AUTOSAR XML (schema 4-0-3)
standard types defined: Boolean, UInt16
package /AUTOSAR_Platform/DataConstrs
  range DC_Boolean: raw 0..1
  range DC_UInt16: raw 0..65535
package /PATAC/MSM/ComponentTypes
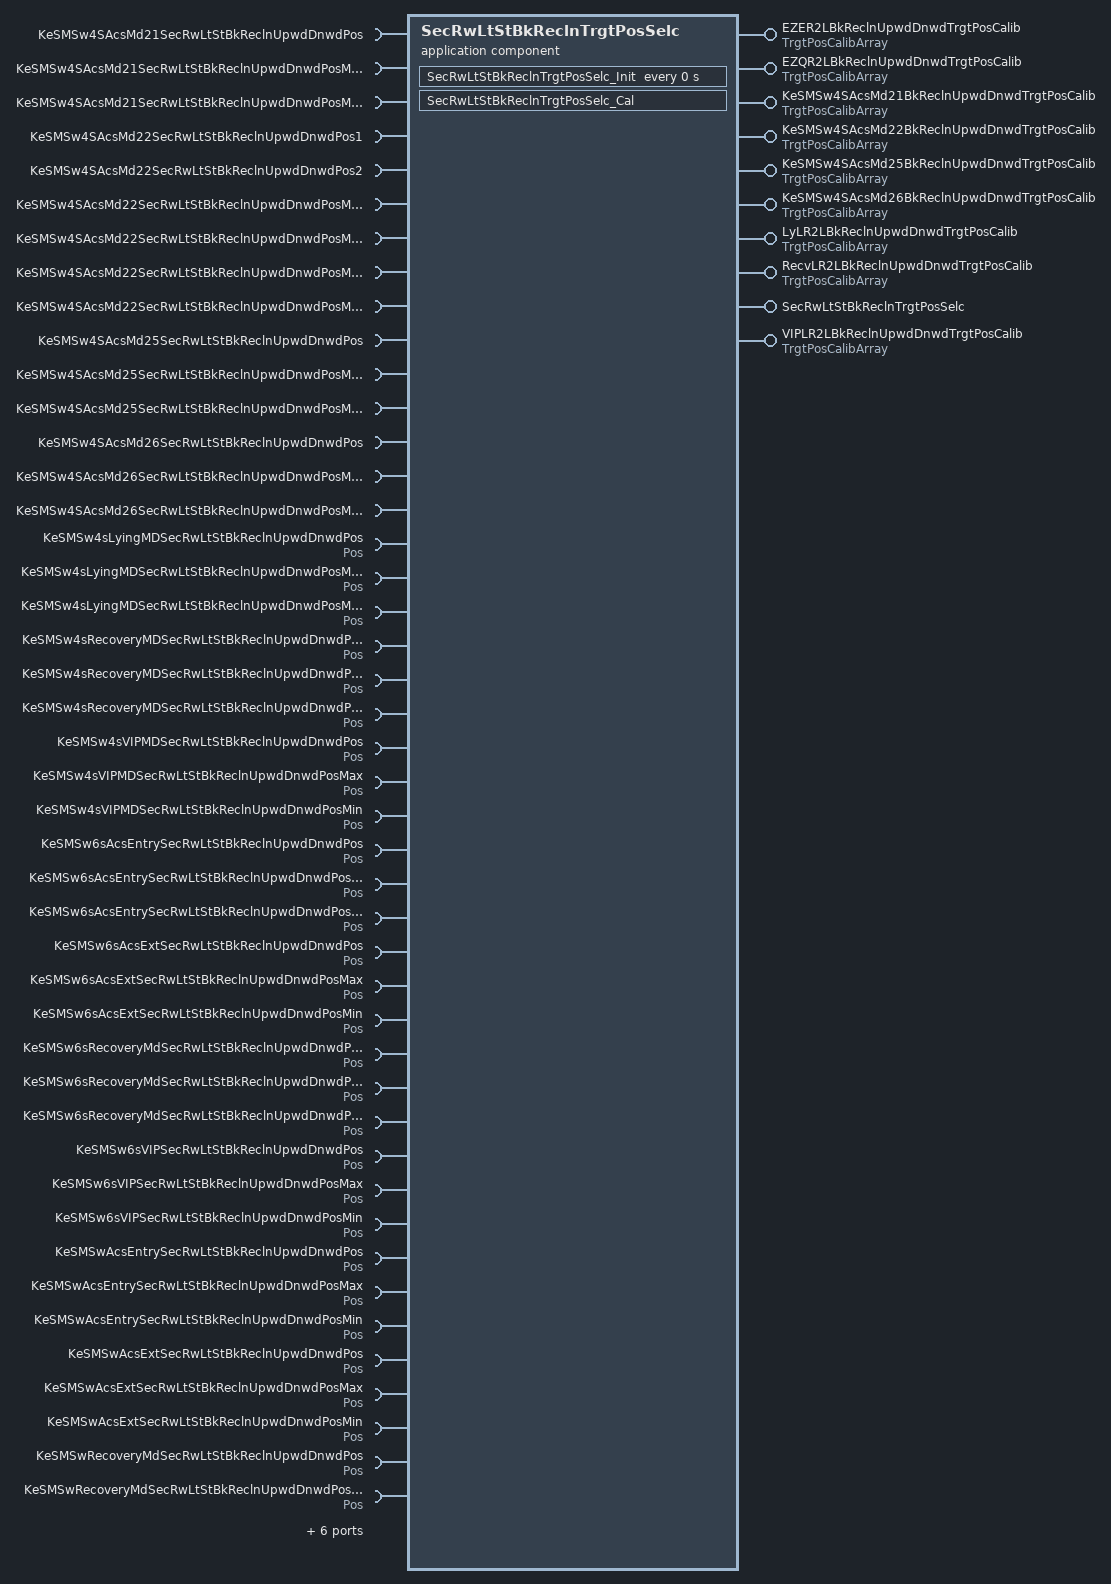
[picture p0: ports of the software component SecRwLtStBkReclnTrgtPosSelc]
  application sw component type SecRwLtStBkReclnTrgtPosSelc
    10 x provide port:
      EZER2LBkReclnUpwdDnwdTrgtPosCalib: nonqueued-sender-com-spec{data-element=TrgtPosArray, init-value=[4095, 4095, 4095]}, provided-interface=TrgtPosCalibArray
      EZQR2LBkReclnUpwdDnwdTrgtPosCalib: nonqueued-sender-com-spec{data-element=TrgtPosArray, init-value=[4095, 4095, 4095]}, provided-interface=TrgtPosCalibArray
      KeSMSw4SAcsMd21BkReclnUpwdDnwdTrgtPosCalib: nonqueued-sender-com-spec{data-element=TrgtPosArray, init-value=[4095, 4095, 4095]}, provided-interface=TrgtPosCalibArray
      KeSMSw4SAcsMd22BkReclnUpwdDnwdTrgtPosCalib: nonqueued-sender-com-spec{data-element=TrgtPosArray, init-value=[4095, 4095, 4095]}, provided-interface=TrgtPosCalibArray
      KeSMSw4SAcsMd25BkReclnUpwdDnwdTrgtPosCalib: nonqueued-sender-com-spec{data-element=TrgtPosArray, init-value=[4095, 4095, 4095]}, provided-interface=TrgtPosCalibArray
      KeSMSw4SAcsMd26BkReclnUpwdDnwdTrgtPosCalib: nonqueued-sender-com-spec{data-element=TrgtPosArray, init-value=[4095, 4095, 4095]}, provided-interface=TrgtPosCalibArray
      LyLR2LBkReclnUpwdDnwdTrgtPosCalib: nonqueued-sender-com-spec{data-element=TrgtPosArray, init-value=[4095, 4095, 4095]}, provided-interface=TrgtPosCalibArray
      RecvLR2LBkReclnUpwdDnwdTrgtPosCalib: nonqueued-sender-com-spec{data-element=TrgtPosArray, init-value=[4095, 4095, 4095]}, provided-interface=TrgtPosCalibArray
      SecRwLtStBkReclnTrgtPosSelc: server-com-spec{operation=Cal, queue-length=1}, provided-interface=SecRwLtStBkReclnTrgtPosSelc
      VIPLR2LBkReclnUpwdDnwdTrgtPosCalib: nonqueued-sender-com-spec{data-element=TrgtPosArray, init-value=[4095, 4095, 4095]}, provided-interface=TrgtPosCalibArray
    50 x require port:
      KeSMSw4SAcsMd21SecRwLtStBkReclnUpwdDnwdPos: parameter-require-com-spec{init-value=0, parameter=KeSMSw4SAcsMd21SecRwLtStBkReclnUpwdDnwdPos/Val}, required-interface=KeSMSw4SAcsMd21SecRwLtStBkReclnUpwdDnwdPos
      KeSMSw4SAcsMd21SecRwLtStBkReclnUpwdDnwdPosMax: parameter-require-com-spec{init-value=0, parameter=KeSMSw4SAcsMd21SecRwLtStBkReclnUpwdDnwdPosMax/Val}, required-interface=KeSMSw4SAcsMd21SecRwLtStBkReclnUpwdDnwdPosMax
      KeSMSw4SAcsMd21SecRwLtStBkReclnUpwdDnwdPosMin: parameter-require-com-spec{init-value=0, parameter=KeSMSw4SAcsMd21SecRwLtStBkReclnUpwdDnwdPosMin/Val}, required-interface=KeSMSw4SAcsMd21SecRwLtStBkReclnUpwdDnwdPosMin
      KeSMSw4SAcsMd22SecRwLtStBkReclnUpwdDnwdPos1: parameter-require-com-spec{init-value=0, parameter=KeSMSw4SAcsMd22SecRwLtStBkReclnUpwdDnwdPos1/Val}, required-interface=KeSMSw4SAcsMd22SecRwLtStBkReclnUpwdDnwdPos1
      KeSMSw4SAcsMd22SecRwLtStBkReclnUpwdDnwdPos2: parameter-require-com-spec{init-value=0, parameter=KeSMSw4SAcsMd22SecRwLtStBkReclnUpwdDnwdPos2/Val}, required-interface=KeSMSw4SAcsMd22SecRwLtStBkReclnUpwdDnwdPos2
      KeSMSw4SAcsMd22SecRwLtStBkReclnUpwdDnwdPosMax1: parameter-require-com-spec{init-value=0, parameter=KeSMSw4SAcsMd22SecRwLtStBkReclnUpwdDnwdPosMax1/Val}, required-interface=KeSMSw4SAcsMd22SecRwLtStBkReclnUpwdDnwdPosMax1
      KeSMSw4SAcsMd22SecRwLtStBkReclnUpwdDnwdPosMax2: parameter-require-com-spec{init-value=0, parameter=KeSMSw4SAcsMd22SecRwLtStBkReclnUpwdDnwdPosMax2/Val}, required-interface=KeSMSw4SAcsMd22SecRwLtStBkReclnUpwdDnwdPosMax2
      KeSMSw4SAcsMd22SecRwLtStBkReclnUpwdDnwdPosMin1: parameter-require-com-spec{init-value=0, parameter=KeSMSw4SAcsMd22SecRwLtStBkReclnUpwdDnwdPosMin1/Val}, required-interface=KeSMSw4SAcsMd22SecRwLtStBkReclnUpwdDnwdPosMin1
      KeSMSw4SAcsMd22SecRwLtStBkReclnUpwdDnwdPosMin2: parameter-require-com-spec{init-value=0, parameter=KeSMSw4SAcsMd22SecRwLtStBkReclnUpwdDnwdPosMin2/Val}, required-interface=KeSMSw4SAcsMd22SecRwLtStBkReclnUpwdDnwdPosMin2
      KeSMSw4SAcsMd25SecRwLtStBkReclnUpwdDnwdPos: parameter-require-com-spec{init-value=0, parameter=KeSMSw4SAcsMd25SecRwLtStBkReclnUpwdDnwdPos/Val}, required-interface=KeSMSw4SAcsMd25SecRwLtStBkReclnUpwdDnwdPos
      KeSMSw4SAcsMd25SecRwLtStBkReclnUpwdDnwdPosMax: parameter-require-com-spec{init-value=0, parameter=KeSMSw4SAcsMd25SecRwLtStBkReclnUpwdDnwdPosMax/Val}, required-interface=KeSMSw4SAcsMd25SecRwLtStBkReclnUpwdDnwdPosMax
      KeSMSw4SAcsMd25SecRwLtStBkReclnUpwdDnwdPosMin: parameter-require-com-spec{init-value=0, parameter=KeSMSw4SAcsMd25SecRwLtStBkReclnUpwdDnwdPosMin/Val}, required-interface=KeSMSw4SAcsMd25SecRwLtStBkReclnUpwdDnwdPosMin
      KeSMSw4SAcsMd26SecRwLtStBkReclnUpwdDnwdPos: parameter-require-com-spec{init-value=0, parameter=KeSMSw4SAcsMd26SecRwLtStBkReclnUpwdDnwdPos/Val}, required-interface=KeSMSw4SAcsMd26SecRwLtStBkReclnUpwdDnwdPos
      KeSMSw4SAcsMd26SecRwLtStBkReclnUpwdDnwdPosMax: parameter-require-com-spec{init-value=0, parameter=KeSMSw4SAcsMd26SecRwLtStBkReclnUpwdDnwdPosMax/Val}, required-interface=KeSMSw4SAcsMd26SecRwLtStBkReclnUpwdDnwdPosMax
      KeSMSw4SAcsMd26SecRwLtStBkReclnUpwdDnwdPosMin: parameter-require-com-spec{init-value=0, parameter=KeSMSw4SAcsMd26SecRwLtStBkReclnUpwdDnwdPosMin/Val}, required-interface=KeSMSw4SAcsMd26SecRwLtStBkReclnUpwdDnwdPosMin
      KeSMSw4sLyingMDSecRwLtStBkReclnUpwdDnwdPos: parameter-require-com-spec{init-value=0, parameter=Pos/Val}, required-interface=Pos
      KeSMSw4sLyingMDSecRwLtStBkReclnUpwdDnwdPosMax: parameter-require-com-spec{init-value=0, parameter=Pos/Val}, required-interface=Pos
      KeSMSw4sLyingMDSecRwLtStBkReclnUpwdDnwdPosMin: parameter-require-com-spec{init-value=0, parameter=Pos/Val}, required-interface=Pos
      KeSMSw4sRecoveryMDSecRwLtStBkReclnUpwdDnwdPos: parameter-require-com-spec{init-value=0, parameter=Pos/Val}, required-interface=Pos
      KeSMSw4sRecoveryMDSecRwLtStBkReclnUpwdDnwdPosMax: parameter-require-com-spec{init-value=0, parameter=Pos/Val}, required-interface=Pos
      KeSMSw4sRecoveryMDSecRwLtStBkReclnUpwdDnwdPosMin: parameter-require-com-spec{init-value=0, parameter=Pos/Val}, required-interface=Pos
      KeSMSw4sVIPMDSecRwLtStBkReclnUpwdDnwdPos: parameter-require-com-spec{init-value=0, parameter=Pos/Val}, required-interface=Pos
      KeSMSw4sVIPMDSecRwLtStBkReclnUpwdDnwdPosMax: parameter-require-com-spec{init-value=0, parameter=Pos/Val}, required-interface=Pos
      KeSMSw4sVIPMDSecRwLtStBkReclnUpwdDnwdPosMin: parameter-require-com-spec{init-value=0, parameter=Pos/Val}, required-interface=Pos
      KeSMSw6sAcsEntrySecRwLtStBkReclnUpwdDnwdPos: parameter-require-com-spec{init-value=1280, parameter=Pos/Val}, required-interface=Pos
      KeSMSw6sAcsEntrySecRwLtStBkReclnUpwdDnwdPosMax: parameter-require-com-spec{init-value=1280, parameter=Pos/Val}, required-interface=Pos
      KeSMSw6sAcsEntrySecRwLtStBkReclnUpwdDnwdPosMin: parameter-require-com-spec{init-value=0, parameter=Pos/Val}, required-interface=Pos
      KeSMSw6sAcsExtSecRwLtStBkReclnUpwdDnwdPos: parameter-require-com-spec{init-value=1280, parameter=Pos/Val}, required-interface=Pos
      KeSMSw6sAcsExtSecRwLtStBkReclnUpwdDnwdPosMax: parameter-require-com-spec{init-value=1280, parameter=Pos/Val}, required-interface=Pos
      KeSMSw6sAcsExtSecRwLtStBkReclnUpwdDnwdPosMin: parameter-require-com-spec{init-value=0, parameter=Pos/Val}, required-interface=Pos
      KeSMSw6sRecoveryMdSecRwLtStBkReclnUpwdDnwdPos: parameter-require-com-spec{init-value=1268, parameter=Pos/Val}, required-interface=Pos
      KeSMSw6sRecoveryMdSecRwLtStBkReclnUpwdDnwdPosMax: parameter-require-com-spec{init-value=1268, parameter=Pos/Val}, required-interface=Pos
      KeSMSw6sRecoveryMdSecRwLtStBkReclnUpwdDnwdPosMin: parameter-require-com-spec{init-value=0, parameter=Pos/Val}, required-interface=Pos
      KeSMSw6sVIPSecRwLtStBkReclnUpwdDnwdPos: parameter-require-com-spec{init-value=1960, parameter=Pos/Val}, required-interface=Pos
      KeSMSw6sVIPSecRwLtStBkReclnUpwdDnwdPosMax: parameter-require-com-spec{init-value=1960, parameter=Pos/Val}, required-interface=Pos
      KeSMSw6sVIPSecRwLtStBkReclnUpwdDnwdPosMin: parameter-require-com-spec{init-value=1960, parameter=Pos/Val}, required-interface=Pos
      KeSMSwAcsEntrySecRwLtStBkReclnUpwdDnwdPos: parameter-require-com-spec{init-value=1280, parameter=Pos/Val}, required-interface=Pos
      KeSMSwAcsEntrySecRwLtStBkReclnUpwdDnwdPosMax: parameter-require-com-spec{init-value=1280, parameter=Pos/Val}, required-interface=Pos
      KeSMSwAcsEntrySecRwLtStBkReclnUpwdDnwdPosMin: parameter-require-com-spec{init-value=0, parameter=Pos/Val}, required-interface=Pos
      KeSMSwAcsExtSecRwLtStBkReclnUpwdDnwdPos: parameter-require-com-spec{init-value=1280, parameter=Pos/Val}, required-interface=Pos
      KeSMSwAcsExtSecRwLtStBkReclnUpwdDnwdPosMax: parameter-require-com-spec{init-value=1280, parameter=Pos/Val}, required-interface=Pos
      KeSMSwAcsExtSecRwLtStBkReclnUpwdDnwdPosMin: parameter-require-com-spec{init-value=0, parameter=Pos/Val}, required-interface=Pos
      KeSMSwRecoveryMdSecRwLtStBkReclnUpwdDnwdPos: parameter-require-com-spec{init-value=1268, parameter=Pos/Val}, required-interface=Pos
      KeSMSwRecoveryMdSecRwLtStBkReclnUpwdDnwdPosMax: parameter-require-com-spec{init-value=1268, parameter=Pos/Val}, required-interface=Pos
      KeSMSwRecoveryMdSecRwLtStBkReclnUpwdDnwdPosMin: parameter-require-com-spec{init-value=0, parameter=Pos/Val}, required-interface=Pos
      KeSMSwVIPSecRwLtStBkReclnUpwdDnwdPos: parameter-require-com-spec{init-value=1960, parameter=Pos/Val}, required-interface=Pos
      KeSMSwVIPSecRwLtStBkReclnUpwdDnwdPosMax: parameter-require-com-spec{init-value=1960, parameter=Pos/Val}, required-interface=Pos
      KeSMSwVIPSecRwLtStBkReclnUpwdDnwdPosMin: parameter-require-com-spec{init-value=1960, parameter=Pos/Val}, required-interface=Pos
      R2LMdSeatOccupied: nonqueued-receiver-com-spec{data-element=Val, filter=data-filter-type=ALWAYS, init-value=0}, required-interface=MdSeatOccupied
      StNumFlg: required-interface=StNumFlg
        required-com-specs:
          data-element=Is4s, filter=data-filter-type=ALWAYS, init-value=0
          data-element=Is6s, filter=data-filter-type=ALWAYS, init-value=0
          data-element=Is6s7s, filter=data-filter-type=ALWAYS, init-value=0
          data-element=Is7s, filter=data-filter-type=ALWAYS, init-value=0
    behavior SecRwLtStBkReclnTrgtPosSelc_InternalBehavior
      operation invoked event OIT_SecRwLtStBkReclnTrgtPosSelc_Cal_SecRwLtStBkReclnTrgtPosSelc_Cal: start-on-event=SecRwLtStBkReclnTrgtPosSelc_Cal, operation=SecRwLtStBkReclnTrgtPosSelc.Cal
      timing event SecRwLtStBkReclnTrgtPosSelc_InitEvent: start-on-event=SecRwLtStBkReclnTrgtPosSelc_Init, period=0
      runnable SecRwLtStBkReclnTrgtPosSelc_Cal
        data-receive-point-by-arguments:
          5 x access:
            REC_R2LMdSeatOccupied_Val: accessed-variable=R2LMdSeatOccupied.Val
            REC_StNumFlg_Is4s: accessed-variable=StNumFlg.Is4s
            REC_StNumFlg_Is6s: accessed-variable=StNumFlg.Is6s
            REC_StNumFlg_Is6s7s: accessed-variable=StNumFlg.Is6s7s
            REC_StNumFlg_Is7s: accessed-variable=StNumFlg.Is7s
        data-send-points:
          9 x access:
            SEND_EZER2LBkReclnUpwdDnwdTrgtPosCalib_TrgtPosArray: accessed-variable=EZER2LBkReclnUpwdDnwdTrgtPosCalib.TrgtPosArray
            SEND_EZQR2LBkReclnUpwdDnwdTrgtPosCalib_TrgtPosArray: accessed-variable=EZQR2LBkReclnUpwdDnwdTrgtPosCalib.TrgtPosArray
            SEND_KeSMSw4SAcsMd21BkReclnUpwdDnwdTrgtPosCalib_TrgtPosArray: accessed-variable=KeSMSw4SAcsMd21BkReclnUpwdDnwdTrgtPosCalib.TrgtPosArray
            SEND_KeSMSw4SAcsMd22BkReclnUpwdDnwdTrgtPosCalib_TrgtPosArray: accessed-variable=KeSMSw4SAcsMd22BkReclnUpwdDnwdTrgtPosCalib.TrgtPosArray
            SEND_KeSMSw4SAcsMd25BkReclnUpwdDnwdTrgtPosCalib_TrgtPosArray: accessed-variable=KeSMSw4SAcsMd25BkReclnUpwdDnwdTrgtPosCalib.TrgtPosArray
            SEND_KeSMSw4SAcsMd26BkReclnUpwdDnwdTrgtPosCalib_TrgtPosArray: accessed-variable=KeSMSw4SAcsMd26BkReclnUpwdDnwdTrgtPosCalib.TrgtPosArray
            SEND_LyLR2LBkReclnUpwdDnwdTrgtPosCalib_TrgtPosArray: accessed-variable=LyLR2LBkReclnUpwdDnwdTrgtPosCalib.TrgtPosArray
            SEND_RecvLR2LBkReclnUpwdDnwdTrgtPosCalib_TrgtPosArray: accessed-variable=RecvLR2LBkReclnUpwdDnwdTrgtPosCalib.TrgtPosArray
            SEND_VIPLR2LBkReclnUpwdDnwdTrgtPosCalib_TrgtPosArray: accessed-variable=VIPLR2LBkReclnUpwdDnwdTrgtPosCalib.TrgtPosArray
        48 x parameter access:
          PA_KeSMSw4SAcsMd21SecRwLtStBkReclnUpwdDnwdPos_Val: accessed-parameter=KeSMSw4SAcsMd21SecRwLtStBkReclnUpwdDnwdPos.Val
          PA_KeSMSw4SAcsMd21SecRwLtStBkReclnUpwdDnwdPosMax_Val: accessed-parameter=KeSMSw4SAcsMd21SecRwLtStBkReclnUpwdDnwdPosMax.Val
          PA_KeSMSw4SAcsMd21SecRwLtStBkReclnUpwdDnwdPosMin_Val: accessed-parameter=KeSMSw4SAcsMd21SecRwLtStBkReclnUpwdDnwdPosMin.Val
          PA_KeSMSw4SAcsMd22SecRwLtStBkReclnUpwdDnwdPos1_Val: accessed-parameter=KeSMSw4SAcsMd22SecRwLtStBkReclnUpwdDnwdPos1.Val
          PA_KeSMSw4SAcsMd22SecRwLtStBkReclnUpwdDnwdPos2_Val: accessed-parameter=KeSMSw4SAcsMd22SecRwLtStBkReclnUpwdDnwdPos2.Val
          PA_KeSMSw4SAcsMd22SecRwLtStBkReclnUpwdDnwdPosMax1_Val: accessed-parameter=KeSMSw4SAcsMd22SecRwLtStBkReclnUpwdDnwdPosMax1.Val
          PA_KeSMSw4SAcsMd22SecRwLtStBkReclnUpwdDnwdPosMax2_Val: accessed-parameter=KeSMSw4SAcsMd22SecRwLtStBkReclnUpwdDnwdPosMax2.Val
          PA_KeSMSw4SAcsMd22SecRwLtStBkReclnUpwdDnwdPosMin1_Val: accessed-parameter=KeSMSw4SAcsMd22SecRwLtStBkReclnUpwdDnwdPosMin1.Val
          PA_KeSMSw4SAcsMd22SecRwLtStBkReclnUpwdDnwdPosMin2_Val: accessed-parameter=KeSMSw4SAcsMd22SecRwLtStBkReclnUpwdDnwdPosMin2.Val
          PA_KeSMSw4SAcsMd25SecRwLtStBkReclnUpwdDnwdPos_Val: accessed-parameter=KeSMSw4SAcsMd25SecRwLtStBkReclnUpwdDnwdPos.Val
          PA_KeSMSw4SAcsMd25SecRwLtStBkReclnUpwdDnwdPosMax_Val: accessed-parameter=KeSMSw4SAcsMd25SecRwLtStBkReclnUpwdDnwdPosMax.Val
          PA_KeSMSw4SAcsMd25SecRwLtStBkReclnUpwdDnwdPosMin_Val: accessed-parameter=KeSMSw4SAcsMd25SecRwLtStBkReclnUpwdDnwdPosMin.Val
          PA_KeSMSw4SAcsMd26SecRwLtStBkReclnUpwdDnwdPos_Val: accessed-parameter=KeSMSw4SAcsMd26SecRwLtStBkReclnUpwdDnwdPos.Val
          PA_KeSMSw4SAcsMd26SecRwLtStBkReclnUpwdDnwdPosMax_Val: accessed-parameter=KeSMSw4SAcsMd26SecRwLtStBkReclnUpwdDnwdPosMax.Val
          PA_KeSMSw4SAcsMd26SecRwLtStBkReclnUpwdDnwdPosMin_Val: accessed-parameter=KeSMSw4SAcsMd26SecRwLtStBkReclnUpwdDnwdPosMin.Val
          PA_KeSMSw4sLyingMDSecRwLtStBkReclnUpwdDnwdPos_Val: accessed-parameter=KeSMSw4sLyingMDSecRwLtStBkReclnUpwdDnwdPos.Val
          PA_KeSMSw4sLyingMDSecRwLtStBkReclnUpwdDnwdPosMax_Val: accessed-parameter=KeSMSw4sLyingMDSecRwLtStBkReclnUpwdDnwdPosMax.Val
          PA_KeSMSw4sLyingMDSecRwLtStBkReclnUpwdDnwdPosMin_Val: accessed-parameter=KeSMSw4sLyingMDSecRwLtStBkReclnUpwdDnwdPosMin.Val
          PA_KeSMSw4sRecoveryMDSecRwLtStBkReclnUpwdDnwdPos_Val: accessed-parameter=KeSMSw4sRecoveryMDSecRwLtStBkReclnUpwdDnwdPos.Val
          PA_KeSMSw4sRecoveryMDSecRwLtStBkReclnUpwdDnwdPosMax_Val: accessed-parameter=KeSMSw4sRecoveryMDSecRwLtStBkReclnUpwdDnwdPosMax.Val
          PA_KeSMSw4sRecoveryMDSecRwLtStBkReclnUpwdDnwdPosMin_Val: accessed-parameter=KeSMSw4sRecoveryMDSecRwLtStBkReclnUpwdDnwdPosMin.Val
          PA_KeSMSw4sVIPMDSecRwLtStBkReclnUpwdDnwdPos_Val: accessed-parameter=KeSMSw4sVIPMDSecRwLtStBkReclnUpwdDnwdPos.Val
          PA_KeSMSw4sVIPMDSecRwLtStBkReclnUpwdDnwdPosMax_Val: accessed-parameter=KeSMSw4sVIPMDSecRwLtStBkReclnUpwdDnwdPosMax.Val
          PA_KeSMSw4sVIPMDSecRwLtStBkReclnUpwdDnwdPosMin_Val: accessed-parameter=KeSMSw4sVIPMDSecRwLtStBkReclnUpwdDnwdPosMin.Val
          PA_KeSMSw6sAcsEntrySecRwLtStBkReclnUpwdDnwdPos_Val: accessed-parameter=KeSMSw6sAcsEntrySecRwLtStBkReclnUpwdDnwdPos.Val
          PA_KeSMSw6sAcsEntrySecRwLtStBkReclnUpwdDnwdPosMax_Val: accessed-parameter=KeSMSw6sAcsEntrySecRwLtStBkReclnUpwdDnwdPosMax.Val
          PA_KeSMSw6sAcsEntrySecRwLtStBkReclnUpwdDnwdPosMin_Val: accessed-parameter=KeSMSw6sAcsEntrySecRwLtStBkReclnUpwdDnwdPosMin.Val
          PA_KeSMSw6sAcsExtSecRwLtStBkReclnUpwdDnwdPos_Val: accessed-parameter=KeSMSw6sAcsExtSecRwLtStBkReclnUpwdDnwdPos.Val
          PA_KeSMSw6sAcsExtSecRwLtStBkReclnUpwdDnwdPosMax_Val: accessed-parameter=KeSMSw6sAcsExtSecRwLtStBkReclnUpwdDnwdPosMax.Val
          PA_KeSMSw6sAcsExtSecRwLtStBkReclnUpwdDnwdPosMin_Val: accessed-parameter=KeSMSw6sAcsExtSecRwLtStBkReclnUpwdDnwdPosMin.Val
          PA_KeSMSw6sRecoveryMdSecRwLtStBkReclnUpwdDnwdPos_Val: accessed-parameter=KeSMSw6sRecoveryMdSecRwLtStBkReclnUpwdDnwdPos.Val
          PA_KeSMSw6sRecoveryMdSecRwLtStBkReclnUpwdDnwdPosMax_Val: accessed-parameter=KeSMSw6sRecoveryMdSecRwLtStBkReclnUpwdDnwdPosMax.Val
          PA_KeSMSw6sRecoveryMdSecRwLtStBkReclnUpwdDnwdPosMin_Val: accessed-parameter=KeSMSw6sRecoveryMdSecRwLtStBkReclnUpwdDnwdPosMin.Val
          PA_KeSMSw6sVIPSecRwLtStBkReclnUpwdDnwdPos_Val: accessed-parameter=KeSMSw6sVIPSecRwLtStBkReclnUpwdDnwdPos.Val
          PA_KeSMSw6sVIPSecRwLtStBkReclnUpwdDnwdPosMax_Val: accessed-parameter=KeSMSw6sVIPSecRwLtStBkReclnUpwdDnwdPosMax.Val
          PA_KeSMSw6sVIPSecRwLtStBkReclnUpwdDnwdPosMin_Val: accessed-parameter=KeSMSw6sVIPSecRwLtStBkReclnUpwdDnwdPosMin.Val
          PA_KeSMSwAcsEntrySecRwLtStBkReclnUpwdDnwdPos_Val: accessed-parameter=KeSMSwAcsEntrySecRwLtStBkReclnUpwdDnwdPos.Val
          PA_KeSMSwAcsEntrySecRwLtStBkReclnUpwdDnwdPosMax_Val: accessed-parameter=KeSMSwAcsEntrySecRwLtStBkReclnUpwdDnwdPosMax.Val
          PA_KeSMSwAcsEntrySecRwLtStBkReclnUpwdDnwdPosMin_Val: accessed-parameter=KeSMSwAcsEntrySecRwLtStBkReclnUpwdDnwdPosMin.Val
          PA_KeSMSwAcsExtSecRwLtStBkReclnUpwdDnwdPos_Val: accessed-parameter=KeSMSwAcsExtSecRwLtStBkReclnUpwdDnwdPos.Val
          PA_KeSMSwAcsExtSecRwLtStBkReclnUpwdDnwdPosMax_Val: accessed-parameter=KeSMSwAcsExtSecRwLtStBkReclnUpwdDnwdPosMax.Val
          PA_KeSMSwAcsExtSecRwLtStBkReclnUpwdDnwdPosMin_Val: accessed-parameter=KeSMSwAcsExtSecRwLtStBkReclnUpwdDnwdPosMin.Val
          PA_KeSMSwRecoveryMdSecRwLtStBkReclnUpwdDnwdPos_Val: accessed-parameter=KeSMSwRecoveryMdSecRwLtStBkReclnUpwdDnwdPos.Val
          PA_KeSMSwRecoveryMdSecRwLtStBkReclnUpwdDnwdPosMax_Val: accessed-parameter=KeSMSwRecoveryMdSecRwLtStBkReclnUpwdDnwdPosMax.Val
          PA_KeSMSwRecoveryMdSecRwLtStBkReclnUpwdDnwdPosMin_Val: accessed-parameter=KeSMSwRecoveryMdSecRwLtStBkReclnUpwdDnwdPosMin.Val
          PA_KeSMSwVIPSecRwLtStBkReclnUpwdDnwdPos_Val: accessed-parameter=KeSMSwVIPSecRwLtStBkReclnUpwdDnwdPos.Val
          PA_KeSMSwVIPSecRwLtStBkReclnUpwdDnwdPosMax_Val: accessed-parameter=KeSMSwVIPSecRwLtStBkReclnUpwdDnwdPosMax.Val
          PA_KeSMSwVIPSecRwLtStBkReclnUpwdDnwdPosMin_Val: accessed-parameter=KeSMSwVIPSecRwLtStBkReclnUpwdDnwdPosMin.Val
      runnable SecRwLtStBkReclnTrgtPosSelc_Init
        48 x parameter access:
          PA_KeSMSw4SAcsMd21SecRwLtStBkReclnUpwdDnwdPos_Val: accessed-parameter=KeSMSw4SAcsMd21SecRwLtStBkReclnUpwdDnwdPos.Val
          PA_KeSMSw4SAcsMd21SecRwLtStBkReclnUpwdDnwdPosMax_Val: accessed-parameter=KeSMSw4SAcsMd21SecRwLtStBkReclnUpwdDnwdPosMax.Val
          PA_KeSMSw4SAcsMd21SecRwLtStBkReclnUpwdDnwdPosMin_Val: accessed-parameter=KeSMSw4SAcsMd21SecRwLtStBkReclnUpwdDnwdPosMin.Val
          PA_KeSMSw4SAcsMd22SecRwLtStBkReclnUpwdDnwdPos1_Val: accessed-parameter=KeSMSw4SAcsMd22SecRwLtStBkReclnUpwdDnwdPos1.Val
          PA_KeSMSw4SAcsMd22SecRwLtStBkReclnUpwdDnwdPos2_Val: accessed-parameter=KeSMSw4SAcsMd22SecRwLtStBkReclnUpwdDnwdPos2.Val
          PA_KeSMSw4SAcsMd22SecRwLtStBkReclnUpwdDnwdPosMax1_Val: accessed-parameter=KeSMSw4SAcsMd22SecRwLtStBkReclnUpwdDnwdPosMax1.Val
          PA_KeSMSw4SAcsMd22SecRwLtStBkReclnUpwdDnwdPosMax2_Val: accessed-parameter=KeSMSw4SAcsMd22SecRwLtStBkReclnUpwdDnwdPosMax2.Val
          PA_KeSMSw4SAcsMd22SecRwLtStBkReclnUpwdDnwdPosMin1_Val: accessed-parameter=KeSMSw4SAcsMd22SecRwLtStBkReclnUpwdDnwdPosMin1.Val
          PA_KeSMSw4SAcsMd22SecRwLtStBkReclnUpwdDnwdPosMin2_Val: accessed-parameter=KeSMSw4SAcsMd22SecRwLtStBkReclnUpwdDnwdPosMin2.Val
          PA_KeSMSw4SAcsMd25SecRwLtStBkReclnUpwdDnwdPos_Val: accessed-parameter=KeSMSw4SAcsMd25SecRwLtStBkReclnUpwdDnwdPos.Val
          PA_KeSMSw4SAcsMd25SecRwLtStBkReclnUpwdDnwdPosMax_Val: accessed-parameter=KeSMSw4SAcsMd25SecRwLtStBkReclnUpwdDnwdPosMax.Val
          PA_KeSMSw4SAcsMd25SecRwLtStBkReclnUpwdDnwdPosMin_Val: accessed-parameter=KeSMSw4SAcsMd25SecRwLtStBkReclnUpwdDnwdPosMin.Val
          PA_KeSMSw4SAcsMd26SecRwLtStBkReclnUpwdDnwdPos_Val: accessed-parameter=KeSMSw4SAcsMd26SecRwLtStBkReclnUpwdDnwdPos.Val
          PA_KeSMSw4SAcsMd26SecRwLtStBkReclnUpwdDnwdPosMax_Val: accessed-parameter=KeSMSw4SAcsMd26SecRwLtStBkReclnUpwdDnwdPosMax.Val
          PA_KeSMSw4SAcsMd26SecRwLtStBkReclnUpwdDnwdPosMin_Val: accessed-parameter=KeSMSw4SAcsMd26SecRwLtStBkReclnUpwdDnwdPosMin.Val
          PA_KeSMSw4sLyingMDSecRwLtStBkReclnUpwdDnwdPos_Val: accessed-parameter=KeSMSw4sLyingMDSecRwLtStBkReclnUpwdDnwdPos.Val
          PA_KeSMSw4sLyingMDSecRwLtStBkReclnUpwdDnwdPosMax_Val: accessed-parameter=KeSMSw4sLyingMDSecRwLtStBkReclnUpwdDnwdPosMax.Val
          PA_KeSMSw4sLyingMDSecRwLtStBkReclnUpwdDnwdPosMin_Val: accessed-parameter=KeSMSw4sLyingMDSecRwLtStBkReclnUpwdDnwdPosMin.Val
          PA_KeSMSw4sRecoveryMDSecRwLtStBkReclnUpwdDnwdPos_Val: accessed-parameter=KeSMSw4sRecoveryMDSecRwLtStBkReclnUpwdDnwdPos.Val
          PA_KeSMSw4sRecoveryMDSecRwLtStBkReclnUpwdDnwdPosMax_Val: accessed-parameter=KeSMSw4sRecoveryMDSecRwLtStBkReclnUpwdDnwdPosMax.Val
          PA_KeSMSw4sRecoveryMDSecRwLtStBkReclnUpwdDnwdPosMin_Val: accessed-parameter=KeSMSw4sRecoveryMDSecRwLtStBkReclnUpwdDnwdPosMin.Val
          PA_KeSMSw4sVIPMDSecRwLtStBkReclnUpwdDnwdPos_Val: accessed-parameter=KeSMSw4sVIPMDSecRwLtStBkReclnUpwdDnwdPos.Val
          PA_KeSMSw4sVIPMDSecRwLtStBkReclnUpwdDnwdPosMax_Val: accessed-parameter=KeSMSw4sVIPMDSecRwLtStBkReclnUpwdDnwdPosMax.Val
          PA_KeSMSw4sVIPMDSecRwLtStBkReclnUpwdDnwdPosMin_Val: accessed-parameter=KeSMSw4sVIPMDSecRwLtStBkReclnUpwdDnwdPosMin.Val
          PA_KeSMSw6sAcsEntrySecRwLtStBkReclnUpwdDnwdPos_Val: accessed-parameter=KeSMSw6sAcsEntrySecRwLtStBkReclnUpwdDnwdPos.Val
          PA_KeSMSw6sAcsEntrySecRwLtStBkReclnUpwdDnwdPosMax_Val: accessed-parameter=KeSMSw6sAcsEntrySecRwLtStBkReclnUpwdDnwdPosMax.Val
          PA_KeSMSw6sAcsEntrySecRwLtStBkReclnUpwdDnwdPosMin_Val: accessed-parameter=KeSMSw6sAcsEntrySecRwLtStBkReclnUpwdDnwdPosMin.Val
          PA_KeSMSw6sAcsExtSecRwLtStBkReclnUpwdDnwdPos_Val: accessed-parameter=KeSMSw6sAcsExtSecRwLtStBkReclnUpwdDnwdPos.Val
          PA_KeSMSw6sAcsExtSecRwLtStBkReclnUpwdDnwdPosMax_Val: accessed-parameter=KeSMSw6sAcsExtSecRwLtStBkReclnUpwdDnwdPosMax.Val
          PA_KeSMSw6sAcsExtSecRwLtStBkReclnUpwdDnwdPosMin_Val: accessed-parameter=KeSMSw6sAcsExtSecRwLtStBkReclnUpwdDnwdPosMin.Val
          PA_KeSMSw6sRecoveryMdSecRwLtStBkReclnUpwdDnwdPos_Val: accessed-parameter=KeSMSw6sRecoveryMdSecRwLtStBkReclnUpwdDnwdPos.Val
          PA_KeSMSw6sRecoveryMdSecRwLtStBkReclnUpwdDnwdPosMax_Val: accessed-parameter=KeSMSw6sRecoveryMdSecRwLtStBkReclnUpwdDnwdPosMax.Val
          PA_KeSMSw6sRecoveryMdSecRwLtStBkReclnUpwdDnwdPosMin_Val: accessed-parameter=KeSMSw6sRecoveryMdSecRwLtStBkReclnUpwdDnwdPosMin.Val
          PA_KeSMSw6sVIPSecRwLtStBkReclnUpwdDnwdPos_Val: accessed-parameter=KeSMSw6sVIPSecRwLtStBkReclnUpwdDnwdPos.Val
          PA_KeSMSw6sVIPSecRwLtStBkReclnUpwdDnwdPosMax_Val: accessed-parameter=KeSMSw6sVIPSecRwLtStBkReclnUpwdDnwdPosMax.Val
          PA_KeSMSw6sVIPSecRwLtStBkReclnUpwdDnwdPosMin_Val: accessed-parameter=KeSMSw6sVIPSecRwLtStBkReclnUpwdDnwdPosMin.Val
          PA_KeSMSwAcsEntrySecRwLtStBkReclnUpwdDnwdPos_Val: accessed-parameter=KeSMSwAcsEntrySecRwLtStBkReclnUpwdDnwdPos.Val
          PA_KeSMSwAcsEntrySecRwLtStBkReclnUpwdDnwdPosMax_Val: accessed-parameter=KeSMSwAcsEntrySecRwLtStBkReclnUpwdDnwdPosMax.Val
          PA_KeSMSwAcsEntrySecRwLtStBkReclnUpwdDnwdPosMin_Val: accessed-parameter=KeSMSwAcsEntrySecRwLtStBkReclnUpwdDnwdPosMin.Val
          PA_KeSMSwAcsExtSecRwLtStBkReclnUpwdDnwdPos_Val: accessed-parameter=KeSMSwAcsExtSecRwLtStBkReclnUpwdDnwdPos.Val
          PA_KeSMSwAcsExtSecRwLtStBkReclnUpwdDnwdPosMax_Val: accessed-parameter=KeSMSwAcsExtSecRwLtStBkReclnUpwdDnwdPosMax.Val
          PA_KeSMSwAcsExtSecRwLtStBkReclnUpwdDnwdPosMin_Val: accessed-parameter=KeSMSwAcsExtSecRwLtStBkReclnUpwdDnwdPosMin.Val
          PA_KeSMSwRecoveryMdSecRwLtStBkReclnUpwdDnwdPos_Val: accessed-parameter=KeSMSwRecoveryMdSecRwLtStBkReclnUpwdDnwdPos.Val
          PA_KeSMSwRecoveryMdSecRwLtStBkReclnUpwdDnwdPosMax_Val: accessed-parameter=KeSMSwRecoveryMdSecRwLtStBkReclnUpwdDnwdPosMax.Val
          PA_KeSMSwRecoveryMdSecRwLtStBkReclnUpwdDnwdPosMin_Val: accessed-parameter=KeSMSwRecoveryMdSecRwLtStBkReclnUpwdDnwdPosMin.Val
          PA_KeSMSwVIPSecRwLtStBkReclnUpwdDnwdPos_Val: accessed-parameter=KeSMSwVIPSecRwLtStBkReclnUpwdDnwdPos.Val
          PA_KeSMSwVIPSecRwLtStBkReclnUpwdDnwdPosMax_Val: accessed-parameter=KeSMSwVIPSecRwLtStBkReclnUpwdDnwdPosMax.Val
          PA_KeSMSwVIPSecRwLtStBkReclnUpwdDnwdPosMin_Val: accessed-parameter=KeSMSwVIPSecRwLtStBkReclnUpwdDnwdPosMin.Val
  swc implementation SecRwLtStBkReclnTrgtPosSelc_Implementation: behavior=SecRwLtStBkReclnTrgtPosSelc_InternalBehavior
    code-descriptors:
      code Default: artifact-descriptors=autosar-engineering-object={short-label=Default, category=SWSRC}
package /PATAC/MSM/ModeAdjust/CalPortInterface
  16 x parameter interface:
    KeSMSw4SAcsMd21SecRwLtStBkReclnUpwdDnwdPos
      parameter data prototype Val: sw-calibration-access=READ-WRITE, type=UInt16
    KeSMSw4SAcsMd21SecRwLtStBkReclnUpwdDnwdPosMax
      parameter data prototype Val: sw-calibration-access=READ-WRITE, type=UInt16
    KeSMSw4SAcsMd21SecRwLtStBkReclnUpwdDnwdPosMin
      parameter data prototype Val: sw-calibration-access=READ-WRITE, type=UInt16
    KeSMSw4SAcsMd22SecRwLtStBkReclnUpwdDnwdPos1
      parameter data prototype Val: sw-calibration-access=READ-WRITE, type=UInt16
    KeSMSw4SAcsMd22SecRwLtStBkReclnUpwdDnwdPos2
      parameter data prototype Val: sw-calibration-access=READ-WRITE, type=UInt16
    KeSMSw4SAcsMd22SecRwLtStBkReclnUpwdDnwdPosMax1
      parameter data prototype Val: sw-calibration-access=READ-WRITE, type=UInt16
    KeSMSw4SAcsMd22SecRwLtStBkReclnUpwdDnwdPosMax2
      parameter data prototype Val: sw-calibration-access=READ-WRITE, type=UInt16
    KeSMSw4SAcsMd22SecRwLtStBkReclnUpwdDnwdPosMin1
      parameter data prototype Val: sw-calibration-access=READ-WRITE, type=UInt16
    KeSMSw4SAcsMd22SecRwLtStBkReclnUpwdDnwdPosMin2
      parameter data prototype Val: sw-calibration-access=READ-WRITE, type=UInt16
    KeSMSw4SAcsMd25SecRwLtStBkReclnUpwdDnwdPos
      parameter data prototype Val: sw-calibration-access=READ-WRITE, type=UInt16
    KeSMSw4SAcsMd25SecRwLtStBkReclnUpwdDnwdPosMax
      parameter data prototype Val: sw-calibration-access=READ-WRITE, type=UInt16
    KeSMSw4SAcsMd25SecRwLtStBkReclnUpwdDnwdPosMin
      parameter data prototype Val: sw-calibration-access=READ-WRITE, type=UInt16
    KeSMSw4SAcsMd26SecRwLtStBkReclnUpwdDnwdPos
      parameter data prototype Val: sw-calibration-access=READ-WRITE, type=UInt16
    KeSMSw4SAcsMd26SecRwLtStBkReclnUpwdDnwdPosMax
      parameter data prototype Val: sw-calibration-access=READ-WRITE, type=UInt16
    KeSMSw4SAcsMd26SecRwLtStBkReclnUpwdDnwdPosMin
      parameter data prototype Val: sw-calibration-access=READ-WRITE, type=UInt16
    Pos
      parameter data prototype Val: sw-calibration-access=READ-WRITE, type=UInt16
package /PATAC/MSM/ModeAdjust/DataType
  impl type TrgtPosCalibArray: category=ARRAY, sw-calibration-access=READ-ONLY, type-emitter=RTE  # 0:pos 1:max 2:min
    element Element: array-size=3, array-size-semantics=FIXED-SIZE, implementation-data-type=UInt16, invalid-value=0
package /PATAC/MSM/ModeAdjust/PortInterface
  client server interface SecRwLtStBkReclnTrgtPosSelc
    operation Cal
  sender receiver interface MdSeatOccupied: invalidation-policy{data-element=Val, handle-invalid=DONT-INVALIDATE}
    data Val: type=Boolean
  sender receiver interface StNumFlg
    4 x data, all with type=Boolean:
      Is4s
      Is6s
      Is6s7s
      Is7s
    invalidation-policys:
      data-element=Is4s, handle-invalid=DONT-INVALIDATE
      data-element=Is6s, handle-invalid=DONT-INVALIDATE
      data-element=Is6s7s, handle-invalid=DONT-INVALIDATE
      data-element=Is7s, handle-invalid=DONT-INVALIDATE
  sender receiver interface TrgtPosCalibArray: invalidation-policy{data-element=TrgtPosArray, handle-invalid=DONT-INVALIDATE}
    data TrgtPosArray: type=TrgtPosCalibArray  # 0:Pos 1:Max 2:Min
